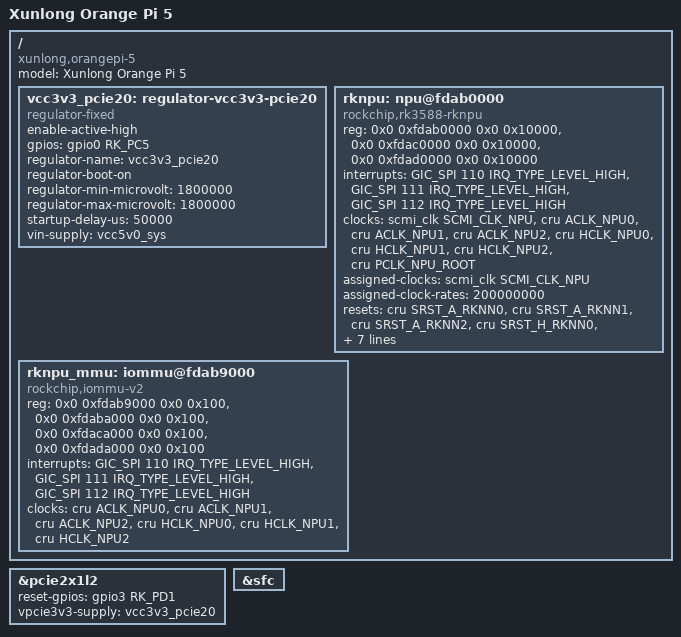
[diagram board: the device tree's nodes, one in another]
// SPDX-License-Identifier: (GPL-2.0+ OR MIT)

/dts-v1/;

#include "rk3588s-orangepi-5.dtsi"

/ {
	model = "Xunlong Orange Pi 5";
	compatible = "xunlong,orangepi-5", "rockchip,rk3588s";

	vcc3v3_pcie20: regulator-vcc3v3-pcie20 {
		compatible = "regulator-fixed";
		enable-active-high;
		gpios = <&gpio0 RK_PC5 GPIO_ACTIVE_HIGH>;
		regulator-name = "vcc3v3_pcie20";
		regulator-boot-on;
		regulator-min-microvolt = <1800000>;
		regulator-max-microvolt = <1800000>;
		startup-delay-us = <50000>;
		vin-supply = <&vcc5v0_sys>;
	};

	rknpu: npu@fdab0000 {
		compatible = "rockchip,rk3588-rknpu";
		reg = <0x0 0xfdab0000 0x0 0x10000>,
		      <0x0 0xfdac0000 0x0 0x10000>,
		      <0x0 0xfdad0000 0x0 0x10000>;
		interrupts = <GIC_SPI 110 IRQ_TYPE_LEVEL_HIGH>,
			     <GIC_SPI 111 IRQ_TYPE_LEVEL_HIGH>,
			     <GIC_SPI 112 IRQ_TYPE_LEVEL_HIGH>;
		interrupt-names = "npu0_irq", "npu1_irq", "npu2_irq";
		clocks = <&scmi_clk SCMI_CLK_NPU>, <&cru ACLK_NPU0>,
			 <&cru ACLK_NPU1>, <&cru ACLK_NPU2>,
			 <&cru HCLK_NPU0>, <&cru HCLK_NPU1>,
			 <&cru HCLK_NPU2>, <&cru PCLK_NPU_ROOT>;
		clock-names = "clk_npu", "aclk0",
			      "aclk1", "aclk2",
			      "hclk0", "hclk1",
			      "hclk2", "pclk";
		assigned-clocks = <&scmi_clk SCMI_CLK_NPU>;
		assigned-clock-rates = <200000000>;
		resets = <&cru SRST_A_RKNN0>, <&cru SRST_A_RKNN1>, <&cru SRST_A_RKNN2>,
			 <&cru SRST_H_RKNN0>, <&cru SRST_H_RKNN1>, <&cru SRST_H_RKNN2>;
		reset-names = "srst_a0", "srst_a1", "srst_a2",
			      "srst_h0", "srst_h1", "srst_h2";
		power-domains = <&power RK3588_PD_NPUTOP>,
				<&power RK3588_PD_NPU1>,
				<&power RK3588_PD_NPU2>;
		power-domain-names = "npu0", "npu1", "npu2";
		operating-points-v2 = <&npu_opp_table>;
		iommus = <&rknpu_mmu>;
		status = "disabled";
	};

	rknpu_mmu: iommu@fdab9000 {
		compatible = "rockchip,iommu-v2";
		reg = <0x0 0xfdab9000 0x0 0x100>,
		      <0x0 0xfdaba000 0x0 0x100>,
		      <0x0 0xfdaca000 0x0 0x100>,
		      <0x0 0xfdada000 0x0 0x100>;
		interrupts = <GIC_SPI 110 IRQ_TYPE_LEVEL_HIGH>,
			     <GIC_SPI 111 IRQ_TYPE_LEVEL_HIGH>,
			     <GIC_SPI 112 IRQ_TYPE_LEVEL_HIGH>;
		interrupt-names = "npu0_mmu", "npu1_mmu", "npu2_mmu";
		clocks = <&cru ACLK_NPU0>, <&cru ACLK_NPU1>, <&cru ACLK_NPU2>,
			 <&cru HCLK_NPU0>, <&cru HCLK_NPU1>, <&cru HCLK_NPU2>;
		clock-names = "aclk0", "aclk1", "aclk2",
			      "iface0", "iface1", "iface2";
		#iommu-cells = <0>;
		status = "disabled";
	};
};

&pcie2x1l2 {
	reset-gpios = <&gpio3 RK_PD1 GPIO_ACTIVE_HIGH>;
	vpcie3v3-supply = <&vcc3v3_pcie20>;
	status = "okay";
};

&sfc {
	status = "okay";
};

&rknpu {
	rknpu-supply = <&vdd_npu_s0>;
	mem-supply = <&vdd_npu_mem_s0>;
	status = "okay";
};

&rknpu_mmu {
	status = "okay";
};
